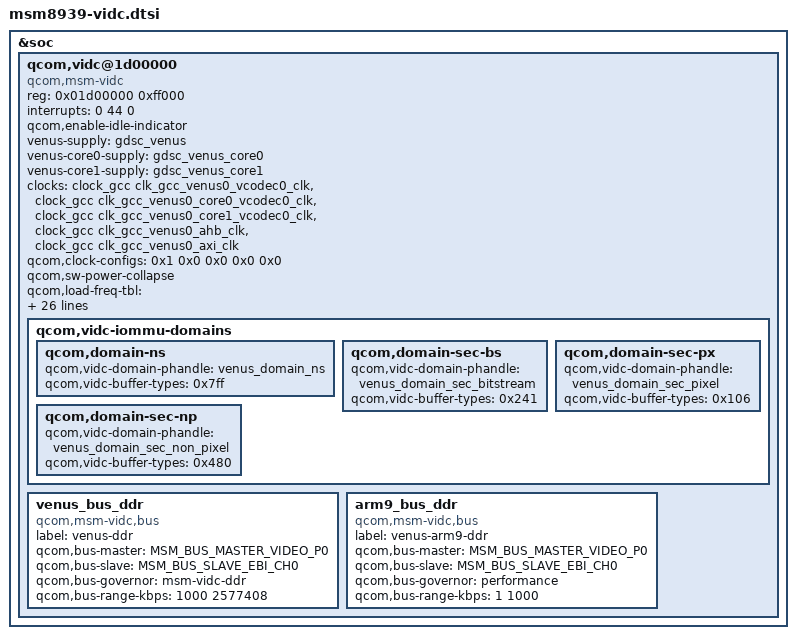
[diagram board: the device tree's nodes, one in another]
/* Copyright (c) 2018, The Linux Foundation. All rights reserved.
 *
 * This program is free software; you can redistribute it and/or modify
 * it under the terms of the GNU General Public License version 2 and
 * only version 2 as published by the Free Software Foundation.
 *
 * This program is distributed in the hope that it will be useful,
 * but WITHOUT ANY WARRANTY; without even the implied warranty of
 * MERCHANTABILITY or FITNESS FOR A PARTICULAR PURPOSE.  See the
 * GNU General Public License for more details.
 */

&soc {
	qcom,vidc@1d00000 {
		compatible = "qcom,msm-vidc";
		reg = <0x01d00000 0xff000>;
		interrupts = <0 44 0>;
		//qcom,hfi-version = "3xx";
		qcom,enable-idle-indicator;
		venus-supply = <&gdsc_venus>;
		venus-core0-supply = <&gdsc_venus_core0>;
		venus-core1-supply = <&gdsc_venus_core1>;
		clocks = <&clock_gcc clk_gcc_venus0_vcodec0_clk>,
			<&clock_gcc clk_gcc_venus0_core0_vcodec0_clk>,
			<&clock_gcc clk_gcc_venus0_core1_vcodec0_clk>,
			<&clock_gcc clk_gcc_venus0_ahb_clk>,
			<&clock_gcc clk_gcc_venus0_axi_clk>;
		clock-names = "core_clk", "core0_clk", "core1_clk", "iface_clk", "bus_clk";
		qcom,clock-configs = <0x1 0x0 0x0 0x0 0x0>;
		qcom,sw-power-collapse;
		qcom,load-freq-tbl =
			<489600 266670000 0x0c000000>, /* HEVC  decoder 1080p 60fps  */
			<489600 266670000 0x030fcfff>, /* Legacy decoder 1080p 60fps  */
			<489600 266670000 0x01000414>, /* Encoder turbo (wfd) */
			<244800 133330000 0x0c000000>, /* HEVC decoder 1080p 30fps   */
			<244800 133330000 0x030ccfff>, /* Legacy decoder 1080p 30fps   */
			<244800 200000000 0x00030000>, /* VC1 decoder 1080p 30fps  */
			<244800 200000000 0x01000414>, /* Legacy encoder 1080p 30fps   */
			<220800 133330000 0x0c000000>, /* HEVC  decoder 720p 60fps  */
			<220800 133330000 0x030fcfff>, /* Legacy decoder 720p 60fps  */
			<108000 133330000 0x0c000000>, /* HEVC decoder 720p 30fps   */
			<108000 133330000 0x030fcfff>, /* Legacy decoder 720p 30fps   */
			<108000 200000000 0x01000414>, /* Legacy encoder 720p 30fps   */
			<72000 133330000 0x0c000000>, /* HEVC decoder VGA 60fps   */
			<72000 133330000 0x030fcfff>, /* Legacy decoder VGA 60fps   */
			<36000 133330000 0x0c000000>, /* HEVC VGA 30 fps  */
			<36000 133330000 0x030fcfff>, /* Legacy decoder VGA 30 fps  */
			<36000 133330000 0x01000414>; /* Legacy encoder VGA 30 fps   */

		qcom,hfi = "venus";
		qcom,reg-presets = <0xE0020 0x0aaaaaaa>,
			<0xE0024 0x0aaaaaaa>,
			<0x80124 0x00000003>;
		qcom,qdss-presets = <0x825000 0x1000>,
			<0x826000 0x1000>,
			<0x821000 0x1000>,
			<0x802000 0x1000>,
			<0x9180000 0x1000>,
			<0x9181000 0x1000>;
		qcom,max-hw-load = <489600>; /* 1080p @ 30 + 1080p @ 30 */
		qcom,firmware-name = "venus";
		qcom,vidc-iommu-domains {
			qcom,domain-ns {
				qcom,vidc-domain-phandle = <&venus_domain_ns>;
				qcom,vidc-buffer-types = <0x7ff>;
			};
			qcom,domain-sec-bs {
				qcom,vidc-domain-phandle = <&venus_domain_sec_bitstream>;
				qcom,vidc-buffer-types = <0x241>;
			};
			qcom,domain-sec-px {
				qcom,vidc-domain-phandle = <&venus_domain_sec_pixel>;
				qcom,vidc-buffer-types = <0x106>;
			};
			qcom,domain-sec-np {
				qcom,vidc-domain-phandle = <&venus_domain_sec_non_pixel>;
				qcom,vidc-buffer-types = <0x480>;
			};
		};
		venus_bus_ddr {
			compatible = "qcom,msm-vidc,bus";
			label = "venus-ddr";
			qcom,bus-master = <MSM_BUS_MASTER_VIDEO_P0>;
			qcom,bus-slave = <MSM_BUS_SLAVE_EBI_CH0>;
			qcom,bus-governor = "msm-vidc-ddr";
			qcom,bus-range-kbps = <1000 2577408>;
		};

		arm9_bus_ddr {
			compatible = "qcom,msm-vidc,bus";
			label = "venus-arm9-ddr";
			qcom,bus-master = <MSM_BUS_MASTER_VIDEO_P0>;
			qcom,bus-slave = <MSM_BUS_SLAVE_EBI_CH0>;
			qcom,bus-governor = "performance";
			qcom,bus-range-kbps = <1 1000>;
		};
	};
};
